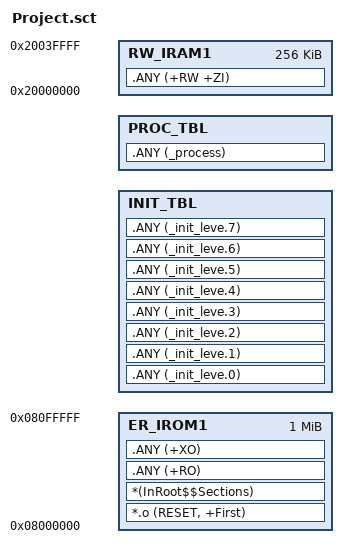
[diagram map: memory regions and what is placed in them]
; *************************************************************
; *** Scatter-Loading Description File generated by uVision ***
; *************************************************************

LR_IROM1 0x08000000 0x00100000  {    ; load region size_region
  ER_IROM1 0x08000000 0x00100000  {  ; load address = execution address
   *.o (RESET, +First)
   *(InRoot$$Sections)
   .ANY (+RO)
   .ANY (+XO)
  }
  INIT_TBL +0 {
    .ANY (_init_leve.0)
    .ANY (_init_leve.1)
    .ANY (_init_leve.2)
    .ANY (_init_leve.3)
    .ANY (_init_leve.4)
    .ANY (_init_leve.5)
    .ANY (_init_leve.6)
    .ANY (_init_leve.7)
  }
  PROC_TBL +0 {
    .ANY (_process)
  }
  RW_IRAM1 0x20000000 0x00040000  {  ; RW data
   .ANY (+RW +ZI)
  }
}

